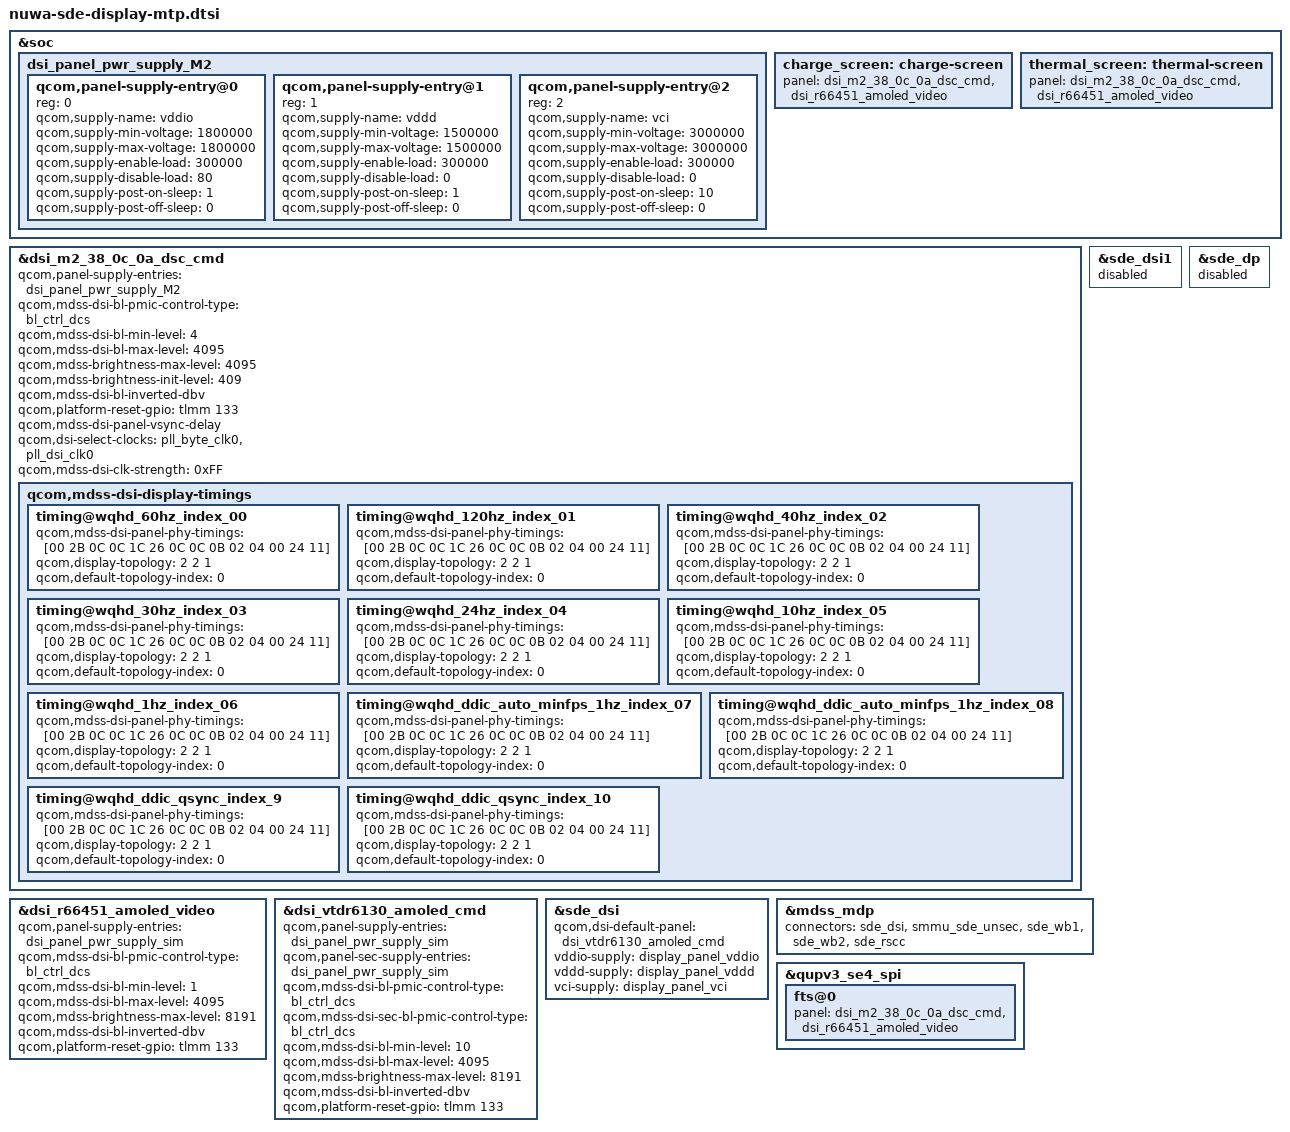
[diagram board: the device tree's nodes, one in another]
#include "kalama-sde-display.dtsi"
#include "dsi-panel-m2-38-0c-0a-dsc-cmd.dtsi"
#include "dsi-panel-m2a-42-02-0b-dsc-cmd.dtsi"

&soc {
	dsi_panel_pwr_supply_M2: dsi_panel_pwr_supply_M2 {
		qcom,panel-supply-entry@0 {
			reg = <0>;
			qcom,supply-name = "vddio";
			qcom,supply-min-voltage = <1800000>;
			qcom,supply-max-voltage = <1800000>;
			qcom,supply-enable-load = <300000>;
			qcom,supply-disable-load = <80>;
			qcom,supply-post-on-sleep = <1>;
			qcom,supply-post-off-sleep = <0>;
		};
		qcom,panel-supply-entry@1 {
			reg = <1>;
			qcom,supply-name = "vddd";
			qcom,supply-min-voltage = <1500000>;
			qcom,supply-max-voltage = <1500000>;
			qcom,supply-enable-load = <300000>;
			qcom,supply-disable-load = <0>;
			qcom,supply-post-on-sleep = <1>;
			qcom,supply-post-off-sleep = <0>;
                };
		qcom,panel-supply-entry@2 {
			reg = <2>;
			qcom,supply-name = "vci";
			qcom,supply-min-voltage = <3000000>;
			qcom,supply-max-voltage = <3000000>;
			qcom,supply-enable-load = <300000>;
			qcom,supply-disable-load = <0>;
			qcom,supply-post-on-sleep = <10>;
			qcom,supply-post-off-sleep = <0>;
		};
	};
};

&dsi_m2_38_0c_0a_dsc_cmd {
	qcom,panel-supply-entries = <&dsi_panel_pwr_supply_M2>;
	qcom,mdss-dsi-bl-pmic-control-type = "bl_ctrl_dcs";
	qcom,mdss-dsi-bl-min-level = <4>;
	qcom,mdss-dsi-bl-max-level = <4095>;
	qcom,mdss-brightness-max-level = <4095>;
	qcom,mdss-brightness-init-level = <409>;
	qcom,mdss-dsi-bl-inverted-dbv;
	qcom,platform-reset-gpio = <&tlmm 133 0>;
	qcom,mdss-dsi-panel-vsync-delay;
	qcom,dsi-select-clocks = "pll_byte_clk0", "pll_dsi_clk0";
	qcom,mdss-dsi-clk-strength = <0xFF>;
	qcom,mdss-dsi-display-timings {
		/* WQHD 60Hz */
		timing@wqhd_60hz_index_00{
			qcom,mdss-dsi-panel-phy-timings = [00 2B 0C 0C 1C 26 0C
				0C 0B 02 04 00 24 11];
			qcom,display-topology = <2 2 1>;
			qcom,default-topology-index = <0>;
		};
		/* WQHD 120hz */
		timing@wqhd_120hz_index_01{
			qcom,mdss-dsi-panel-phy-timings = [00 2B 0C 0C 1C 26 0C
				0C 0B 02 04 00 24 11];
			qcom,display-topology = <2 2 1>;
			qcom,default-topology-index = <0>;
		};
		/* WQHD 40hz */
		timing@wqhd_40hz_index_02{
			qcom,mdss-dsi-panel-phy-timings = [00 2B 0C 0C 1C 26 0C
				0C 0B 02 04 00 24 11];
			qcom,display-topology = <2 2 1>;
			qcom,default-topology-index = <0>;
		};
		/* WQHD 30hz */
		timing@wqhd_30hz_index_03{
			qcom,mdss-dsi-panel-phy-timings = [00 2B 0C 0C 1C 26 0C
				0C 0B 02 04 00 24 11];
			qcom,display-topology = <2 2 1>;
			qcom,default-topology-index = <0>;
		};
		/* WQHD 24hz */
		timing@wqhd_24hz_index_04{
			qcom,mdss-dsi-panel-phy-timings = [00 2B 0C 0C 1C 26 0C
				0C 0B 02 04 00 24 11];
			qcom,display-topology = <2 2 1>;
			qcom,default-topology-index = <0>;
		};
		/* WQHD 10hz */
		timing@wqhd_10hz_index_05{
			qcom,mdss-dsi-panel-phy-timings = [00 2B 0C 0C 1C 26 0C
				0C 0B 02 04 00 24 11];
			qcom,display-topology = <2 2 1>;
			qcom,default-topology-index = <0>;
		};
		/* WQHD 1hz */
		timing@wqhd_1hz_index_06{
			qcom,mdss-dsi-panel-phy-timings = [00 2B 0C 0C 1C 26 0C
				0C 0B 02 04 00 24 11];
			qcom,display-topology = <2 2 1>;
			qcom,default-topology-index = <0>;
		};
		/* WQHD ddic auto mode , min fps 1hz */
		timing@wqhd_ddic_auto_minfps_1hz_index_07{
			qcom,mdss-dsi-panel-phy-timings = [00 2B 0C 0C 1C 26 0C
				0C 0B 02 04 00 24 11];
			qcom,display-topology = <2 2 1>;
			qcom,default-topology-index = <0>;
		};
		/* WQHD ddic auto mode , min fps 1hz */
		timing@wqhd_ddic_auto_minfps_1hz_index_08{
			qcom,mdss-dsi-panel-phy-timings = [00 2B 0C 0C 1C 26 0C
				0C 0B 02 04 00 24 11];
			qcom,display-topology = <2 2 1>;
			qcom,default-topology-index = <0>;
		};
		/* WQHD ddic qsync mode , min fps 10hz */
		timing@wqhd_ddic_qsync_index_9{
			qcom,mdss-dsi-panel-phy-timings = [00 2B 0C 0C 1C 26 0C
				0C 0B 02 04 00 24 11];
			qcom,display-topology = <2 2 1>;
			qcom,default-topology-index = <0>;
		};
		/* WQHD ddic qsync mode , min fps 10hz */
		timing@wqhd_ddic_qsync_index_10{
			qcom,mdss-dsi-panel-phy-timings = [00 2B 0C 0C 1C 26 0C
				0C 0B 02 04 00 24 11];
			qcom,display-topology = <2 2 1>;
			qcom,default-topology-index = <0>;
		};
	};
};

&dsi_r66451_amoled_video {
	qcom,panel-supply-entries = <&dsi_panel_pwr_supply_sim>;
	qcom,mdss-dsi-bl-pmic-control-type = "bl_ctrl_dcs";
	qcom,mdss-dsi-bl-min-level = <1>;
	qcom,mdss-dsi-bl-max-level = <4095>;
	qcom,mdss-brightness-max-level = <8191>;
	qcom,mdss-dsi-bl-inverted-dbv;
	qcom,platform-reset-gpio = <&tlmm 133 0>;
	/delete-property/qcom,esd-check-enabled;
};

&dsi_vtdr6130_amoled_cmd {
	qcom,panel-supply-entries = <&dsi_panel_pwr_supply_sim>;
	qcom,panel-sec-supply-entries = <&dsi_panel_pwr_supply_sim>;
	qcom,mdss-dsi-bl-pmic-control-type = "bl_ctrl_dcs";
	qcom,mdss-dsi-sec-bl-pmic-control-type = "bl_ctrl_dcs";
	qcom,mdss-dsi-bl-min-level = <10>;
	qcom,mdss-dsi-bl-max-level = <4095>;
	qcom,mdss-brightness-max-level = <8191>;
	qcom,mdss-dsi-bl-inverted-dbv;
	qcom,platform-reset-gpio = <&tlmm 133 0>;
	/delete-property/qcom,esd-check-enabled;
};

&sde_dsi {
	qcom,dsi-default-panel = <&dsi_vtdr6130_amoled_cmd>;
	vddio-supply = <&display_panel_vddio>;
	vddd-supply = <&display_panel_vddd>;
	vci-supply = <&display_panel_vci>;
};

&sde_dsi1 {
	status = "disabled";
};

&sde_dp {
	status = "disabled";
};

&mdss_mdp {
        connectors = <&sde_dsi &smmu_sde_unsec &sde_wb1 &sde_wb2 &sde_rscc>;
};

&qupv3_se4_spi {
	fts@0 {
		panel = <&dsi_m2_38_0c_0a_dsc_cmd
			&dsi_r66451_amoled_video>;
	};
};

&soc {
	charge_screen: charge-screen {
		panel  = <&dsi_m2_38_0c_0a_dsc_cmd
			&dsi_r66451_amoled_video>;
	};

};

&soc {
	thermal_screen: thermal-screen {
		panel = <&dsi_m2_38_0c_0a_dsc_cmd
			&dsi_r66451_amoled_video>;
        };
};

